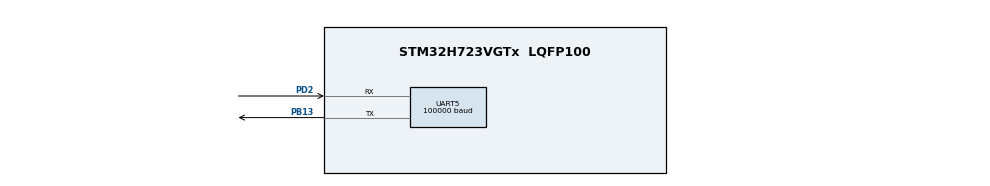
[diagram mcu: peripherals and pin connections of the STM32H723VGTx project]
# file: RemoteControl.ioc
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CORTEX_M7.default_mode_Activation=0
Dma.Request0=UART5_RX
Dma.UART5_RX.0.Direction=DMA_PERIPH_TO_MEMORY
Dma.UART5_RX.0.EventEnable=DISABLE
Dma.UART5_RX.0.FIFOMode=DMA_FIFOMODE_DISABLE
Dma.UART5_RX.0.Instance=DMA1_Stream0
Dma.UART5_RX.0.MemDataAlignment=DMA_MDATAALIGN_BYTE
Dma.UART5_RX.0.MemInc=DMA_MINC_ENABLE
Dma.UART5_RX.0.Mode=DMA_CIRCULAR
Dma.UART5_RX.0.PeriphDataAlignment=DMA_PDATAALIGN_BYTE
Dma.UART5_RX.0.PeriphInc=DMA_PINC_DISABLE
Dma.UART5_RX.0.Polarity=HAL_DMAMUX_REQ_GEN_RISING
Dma.UART5_RX.0.Priority=DMA_PRIORITY_VERY_HIGH
Dma.UART5_RX.0.RequestNumber=1
Dma.UART5_RX.0.SignalID=NONE
Dma.UART5_RX.0.SyncEnable=DISABLE
Dma.UART5_RX.0.SyncPolarity=HAL_DMAMUX_SYNC_NO_EVENT
Dma.UART5_RX.0.SyncRequestNumber=1
Dma.UART5_RX.0.SyncSignalID=NONE
Mcu.Family=STM32H7
Mcu.Name=STM32H723VGTx
Mcu.Package=LQFP100
NVIC.DMA1_Stream0_IRQn=true\:0\:0\:false\:false\:true\:false\:true\:true
NVIC.PriorityGroup=NVIC_PRIORITYGROUP_4
NVIC.UART5_IRQn=true\:0\:0\:false\:false\:true\:true\:true\:true
PB13.Mode=Asynchronous
PB13.Signal=UART5_TX
PD2.Mode=Asynchronous
PD2.Signal=UART5_RX
PH0-OSC_IN.Mode=HSE-External-Oscillator
PH0-OSC_IN.Signal=RCC_OSC_IN
PH1-OSC_OUT.Mode=HSE-External-Oscillator
PH1-OSC_OUT.Signal=RCC_OSC_OUT
ProjectManager.HeapSize=0x200
ProjectManager.StackSize=0x400
ProjectManager.TargetToolchain=MDK-ARM V5.32
RCC.ADCFreq_Value=48375000
RCC.APB1Freq_Value=120000000
RCC.APB2Freq_Value=120000000
RCC.APB3Freq_Value=120000000
RCC.APB4Freq_Value=120000000
RCC.CortexFreq_Value=480000000
RCC.D1PPRE=RCC_APB3_DIV2
RCC.D2PPRE1=RCC_APB1_DIV2
RCC.D2PPRE2=RCC_APB2_DIV2
RCC.D3PPRE=RCC_APB4_DIV2
RCC.DIVM1=2
RCC.DIVN1=40
RCC.DIVP1=1
RCC.HCLKFreq_Value=240000000
RCC.HPRE=RCC_HCLK_DIV2
RCC.HSE_VALUE=24000000
RCC.PLLFRACN=0
RCC.PLLSourceVirtual=RCC_PLLSOURCE_HSE
RCC.SYSCLKFreq_VALUE=480000000
RCC.SYSCLKSource=RCC_SYSCLKSOURCE_PLLCLK
RCC.USBFreq_Value=240000000
UART5.BaudRate=100000
UART5.Parity=PARITY_EVEN
UART5.StopBits=UART_STOPBITS_2
UART5.WordLength=WORDLENGTH_9B
board=custom

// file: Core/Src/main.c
/* USER CODE BEGIN Header */
/**
 ******************************************************************************
 * @file           : main.c
 * @brief          : Main program body
 ******************************************************************************
 * @attention
 *
 * Copyright (c) 2026 STMicroelectronics.
 * All rights reserved.
 *
 * This software is licensed under terms that can be found in the LICENSE file
 * in the root directory of this software component.
 * If no LICENSE file comes with this software, it is provided AS-IS.
 *
 ******************************************************************************
 */
/* USER CODE END Header */
#include "main.h"
#include "dma.h"
#include "usart.h"
#include "gpio.h"

/* USER CODE BEGIN PTD */

// 定义遥控器控制值的结构体（其实吧，我感觉把自己定义的全部放在Private variables也是没问题的，更直观）
typedef struct
{
  int16_t ch[4];
  uint8_t s[2];
} RC_Ctl_t;

/* USER CODE END PTD */

/* USER CODE BEGIN PD */

// 定义DBUS数据包的长度为18字节
#define DBUS_RX_BUF_NUM 18 // 单个接收缓冲区的字节长度
#define RC_FRAME_LENGTH 18 // DBUS数据包的长度为18字节
#define OFFSET 1024
/* USER CODE END PD */

/* USER CODE BEGIN PV */

// 定义双缓冲区
uint8_t DBUS_MultiRx_Buf[2][DBUS_RX_BUF_NUM] = {0};

// 定义全局的遥控器控制值变量
RC_Ctl_t remote_ctrl = {0};

/* USER CODE END PV */

void SystemClock_Config(void);
/* USER CODE BEGIN PFP */
void USART_DMAEx_MultiBuffer_Init(UART_HandleTypeDef *huart, uint32_t *DstAddress, uint32_t *SecondMemAddress, uint32_t DataLength);
void DBUS_TO_RC(uint8_t *dbus_buf, RC_Ctl_t *rc_ctrl);
void USER_USART5_RxHandler(UART_HandleTypeDef *huart,uint16_t Size);
/* USER CODE END PFP */

/* USER CODE BEGIN 0 */

/*
    HAL库函数初始化DMA双缓冲模式
*/
void USART_DMAEx_MultiBuffer_Init(UART_HandleTypeDef *huart, uint32_t *DstAddress, uint32_t *SecondMemAddress, uint32_t DataLength)
{
 huart->ReceptionType = HAL_UART_RECEPTION_TOIDLE;

 huart->RxEventType = HAL_UART_RXEVENT_IDLE;

 huart->RxXferSize    = DataLength;

 SET_BIT(huart->Instance->CR3,USART_CR3_DMAR);

 __HAL_UART_ENABLE_IT(huart, UART_IT_IDLE);

do{
      __HAL_DMA_DISABLE(huart->hdmarx);
  }while(((DMA_Stream_TypeDef  *)huart->hdmarx->Instance)->CR & DMA_SxCR_EN);

((DMA_Stream_TypeDef  *)huart->hdmarx->Instance)->PAR = (uint32_t)&huart->Instance->RDR;

((DMA_Stream_TypeDef  *)huart->hdmarx->Instance)->M0AR = (uint32_t)DstAddress;

((DMA_Stream_TypeDef  *)huart->hdmarx->Instance)->M1AR = (uint32_t)SecondMemAddress;

((DMA_Stream_TypeDef  *)huart->hdmarx->Instance)->NDTR = DataLength;

SET_BIT(((DMA_Stream_TypeDef  *)huart->hdmarx->Instance)->CR, DMA_SxCR_DBM);

__HAL_DMA_ENABLE(huart->hdmarx);
}

/*
static void USART_RxDMA_DoubleBuffer_Init(UART_HandleTypeDef *huart, uint32_t *DstAddress, uint32_t *SecondMemAddress, uint32_t DataLength)
{
 huart->ReceptionType = HAL_UART_RECEPTION_TOIDLE;

 huart->RxEventType = HAL_UART_RXEVENT_IDLE;

 huart->RxXferSize    = DataLength;

 SET_BIT(huart->Instance->CR3,USART_CR3_DMAR);

 __HAL_UART_ENABLE_IT(huart, UART_IT_IDLE);

 HAL_DMAEx_MultiBufferStart(huart->hdmarx,(uint32_t)&huart->Instance->RDR,(uint32_t)DstAddress,(uint32_t)SecondMemAddress,DataLength);
 }
*/

/*
    解析DBUS数据包，并将其映射到遥控器控制值变量中
*/
void DBUS_TO_RC(uint8_t *dbus_buf, RC_Ctl_t *rc_ctrl)
{
  // 校验指针有效性，确保数据有效
  if (dbus_buf == NULL || rc_ctrl == NULL)
  {
    return;
  }

  rc_ctrl->ch[0] = (((int16_t)dbus_buf[0] | ((int16_t)dbus_buf[1] << 8)) & 0x07FF) - OFFSET;
  rc_ctrl->ch[1] = ((((int16_t)dbus_buf[1] >> 3) | ((int16_t)dbus_buf[2] << 5)) & 0x07FF) - OFFSET;
  rc_ctrl->ch[2] = ((((int16_t)dbus_buf[2] >> 6) | ((int16_t)dbus_buf[3] << 2) | ((int16_t)dbus_buf[4] << 10)) & 0x07FF) - OFFSET;
  rc_ctrl->ch[3] = ((((int16_t)dbus_buf[4] >> 1) | ((int16_t)dbus_buf[5] << 7)) & 0x07FF) - OFFSET;

  // 解析开关
  rc_ctrl->s[0] = ((dbus_buf[5] >> 4) & 0x000C) >> 2;
  rc_ctrl->s[1] = ((dbus_buf[5] >> 4) & 0x0003);
}

void USER_USART5_RxHandler(UART_HandleTypeDef *huart,uint16_t Size){

 if(((((DMA_Stream_TypeDef  *)huart->hdmarx->Instance)->CR) & DMA_SxCR_CT ) == RESET)
 {
	  __HAL_DMA_DISABLE(huart->hdmarx);

	  ((DMA_Stream_TypeDef  *)huart->hdmarx->Instance)->CR |= DMA_SxCR_CT;

    __HAL_DMA_SET_COUNTER(huart->hdmarx, DBUS_RX_BUF_NUM * 2);

    if (Size == DBUS_RX_BUF_NUM)
    {
		DBUS_TO_RC(DBUS_MultiRx_Buf[0],&remote_ctrl);
	  }

 }else{
	 __HAL_DMA_DISABLE(huart->hdmarx);

	  ((DMA_Stream_TypeDef  *)huart->hdmarx->Instance)->CR &= ~(DMA_SxCR_CT);

    __HAL_DMA_SET_COUNTER(huart->hdmarx, DBUS_RX_BUF_NUM * 2);

    if (Size == DBUS_RX_BUF_NUM)
    {
		DBUS_TO_RC(DBUS_MultiRx_Buf[1],&remote_ctrl);
	  }
 }
		 __HAL_DMA_ENABLE(huart->hdmarx);
}

void HAL_UARTEx_RxEventCallback(UART_HandleTypeDef *huart, uint16_t Size)
{
  if (huart == &huart5)
  {
    USER_USART5_RxHandler(huart, Size);
  }
}

/* USER CODE END 0 */

int main(void)
{

  /* MCU Configuration--------------------------------------------------------*/

  /* Reset of all peripherals, Initializes the Flash interface and the Systick. */
  HAL_Init();

  /* Configure the system clock */
  SystemClock_Config();

  /* Initialize all configured peripherals */
  MX_GPIO_Init();
  MX_DMA_Init();
  MX_UART5_Init();
  /* USER CODE BEGIN 2 */
  USART_DMAEx_MultiBuffer_Init(&huart5, (uint32_t *)DBUS_MultiRx_Buf[0],
                               (uint32_t *)DBUS_MultiRx_Buf[1], DBUS_RX_BUF_NUM * 2);
  /* USER CODE END 2 */

  /* Infinite loop */
  while (1)
  {

  }
}

void SystemClock_Config(void)
{
  RCC_OscInitTypeDef RCC_OscInitStruct = {0};
  RCC_ClkInitTypeDef RCC_ClkInitStruct = {0};

  /** Supply configuration update enable
  */
  HAL_PWREx_ConfigSupply(PWR_LDO_SUPPLY);

  /** Configure the main internal regulator output voltage
  */
  __HAL_PWR_VOLTAGESCALING_CONFIG(PWR_REGULATOR_VOLTAGE_SCALE0);

  while(!__HAL_PWR_GET_FLAG(PWR_FLAG_VOSRDY)) {}

  /** Initializes the RCC Oscillators according to the specified parameters
  * in the RCC_OscInitTypeDef structure.
  */
  RCC_OscInitStruct.OscillatorType = RCC_OSCILLATORTYPE_HSE;
  RCC_OscInitStruct.HSEState = RCC_HSE_ON;
  RCC_OscInitStruct.PLL.PLLState = RCC_PLL_ON;
  RCC_OscInitStruct.PLL.PLLSource = RCC_PLLSOURCE_HSE;
  RCC_OscInitStruct.PLL.PLLM = 2;
  RCC_OscInitStruct.PLL.PLLN = 40;
  RCC_OscInitStruct.PLL.PLLP = 1;
  RCC_OscInitStruct.PLL.PLLQ = 2;
  RCC_OscInitStruct.PLL.PLLR = 2;
  RCC_OscInitStruct.PLL.PLLRGE = RCC_PLL1VCIRANGE_3;
  RCC_OscInitStruct.PLL.PLLVCOSEL = RCC_PLL1VCOWIDE;
  RCC_OscInitStruct.PLL.PLLFRACN = 0;
  if (HAL_RCC_OscConfig(&RCC_OscInitStruct) != HAL_OK)
  {
    Error_Handler();
  }

  /** Initializes the CPU, AHB and APB buses clocks
  */
  RCC_ClkInitStruct.ClockType = RCC_CLOCKTYPE_HCLK|RCC_CLOCKTYPE_SYSCLK
                              |RCC_CLOCKTYPE_PCLK1|RCC_CLOCKTYPE_PCLK2
                              |RCC_CLOCKTYPE_D3PCLK1|RCC_CLOCKTYPE_D1PCLK1;
  RCC_ClkInitStruct.SYSCLKSource = RCC_SYSCLKSOURCE_PLLCLK;
  RCC_ClkInitStruct.SYSCLKDivider = RCC_SYSCLK_DIV1;
  RCC_ClkInitStruct.AHBCLKDivider = RCC_HCLK_DIV2;
  RCC_ClkInitStruct.APB3CLKDivider = RCC_APB3_DIV2;
  RCC_ClkInitStruct.APB1CLKDivider = RCC_APB1_DIV2;
  RCC_ClkInitStruct.APB2CLKDivider = RCC_APB2_DIV2;
  RCC_ClkInitStruct.APB4CLKDivider = RCC_APB4_DIV2;

  if (HAL_RCC_ClockConfig(&RCC_ClkInitStruct, FLASH_LATENCY_3) != HAL_OK)
  {
    Error_Handler();
  }
}

void Error_Handler(void)
{
  __disable_irq();
  while (1)
  {
  }
}
